# nrf5002 register map
Vendor: Nordic Semiconductor; Series: nRF50; File version: 1
CPU: CM0 r0p4, little endian, no MPU, no FPU, 2 interrupt priority bits, 32 interrupts
Registers are 32-bit, read-write, reset 0x0 unless marked. A register's access mark holds for its fields unless they carry their own. Offsets are from the block's base; [hi:lo] are bit positions; 'fields as' and 'values as' point back to an identical list.

## AAR — Accelerated Address Resolver
Base 0x4000A000; alternate view of CCM
0x00 TASKS_START wo — Start resolving addresses based on IRKs specified in the IRK data structure
  [0] TASKS_START
    1=Trigger task
0x08 TASKS_STOP wo — Stop resolving addresses
  [0] TASKS_STOP
    1=Trigger task
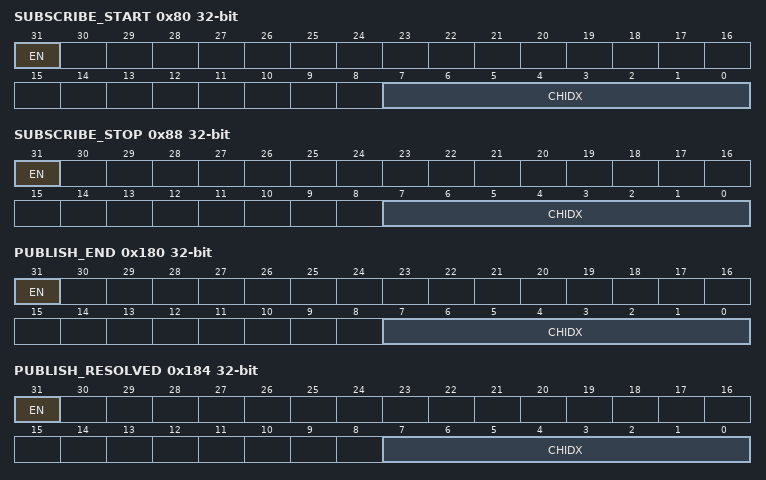
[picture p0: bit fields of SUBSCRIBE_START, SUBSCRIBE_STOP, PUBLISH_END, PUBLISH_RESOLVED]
0x80 SUBSCRIBE_START — Subscribe configuration for task START
  [31] EN
    0=Disabled (Disable subscription); 1=Enabled (Enable subscription)
  [7:0] CHIDX — DPPI channel that task START will subscribe to
0x88 SUBSCRIBE_STOP — Subscribe configuration for task STOP
  [31] EN
    values as SUBSCRIBE_START.EN
  [7:0] CHIDX — DPPI channel that task STOP will subscribe to
0x100 EVENTS_END — Address resolution procedure complete
  [0] EVENTS_END
    0=NotGenerated (Event not generated); 1=Generated (Event generated)
0x104 EVENTS_RESOLVED — Address resolved
  [0] EVENTS_RESOLVED
    values as EVENTS_END.EVENTS_END
0x108 EVENTS_NOTRESOLVED — Address not resolved
  [0] EVENTS_NOTRESOLVED
    values as EVENTS_END.EVENTS_END
0x180 PUBLISH_END — Publish configuration for event END
  [31] EN
    0=Disabled (Disable publishing); 1=Enabled (Enable publishing)
  [7:0] CHIDX — DPPI channel that event END will publish to
0x184 PUBLISH_RESOLVED — Publish configuration for event RESOLVED
  [31] EN
    values as PUBLISH_END.EN
  [7:0] CHIDX — DPPI channel that event RESOLVED will publish to
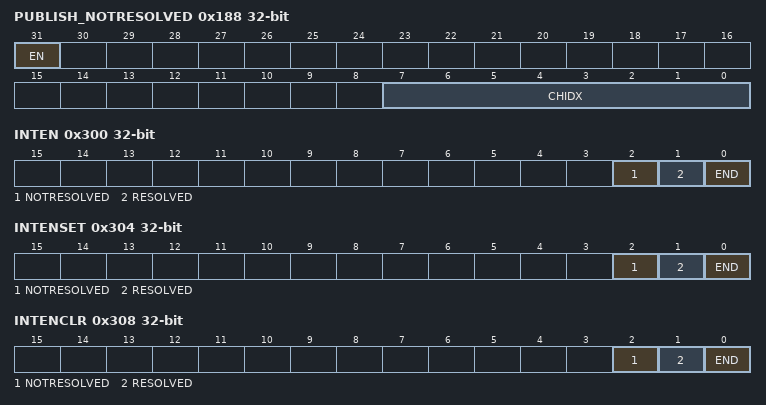
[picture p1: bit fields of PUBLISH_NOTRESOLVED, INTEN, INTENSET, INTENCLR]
0x188 PUBLISH_NOTRESOLVED — Publish configuration for event NOTRESOLVED
  [31] EN
    values as PUBLISH_END.EN
  [7:0] CHIDX — DPPI channel that event NOTRESOLVED will publish to
0x300 INTEN — Enable or disable interrupt
  [all] fields
    0=Disabled; 1=Enabled
  [2] NOTRESOLVED — Enable or disable interrupt for event NOTRESOLVED
  [1] RESOLVED — Enable or disable interrupt for event RESOLVED
  [0] END — Enable or disable interrupt for event END
0x304 INTENSET — Enable interrupt
  [all] fields
    on read: 0=Disabled (Read: Disabled); 1=Enabled (Read: Enabled) | on write: 1=Set (Enable)
  [2] NOTRESOLVED — Write '1' to enable interrupt for event NOTRESOLVED
  [1] RESOLVED — Write '1' to enable interrupt for event RESOLVED
  [0] END — Write '1' to enable interrupt for event END
0x308 INTENCLR — Disable interrupt
  [all] fields
    on read: 0=Disabled (Read: Disabled); 1=Enabled (Read: Enabled) | on write: 1=Clear (Disable)
  [2] NOTRESOLVED — Write '1' to disable interrupt for event NOTRESOLVED
  [1] RESOLVED — Write '1' to disable interrupt for event RESOLVED
  [0] END — Write '1' to disable interrupt for event END
0x400 STATUS ro — Resolution status
  [3:0] STATUS — The IRK that was used last time an address was resolved
0x500 ENABLE — Enable AAR
  [1:0] ENABLE — Enable or disable AAR
    0=Disabled; 3=Enabled
0x504 NIRK reset 0x1 — Number of IRKs
  [4:0] NIRK — Number of Identity root keys available in the IRK data structure
0x508 IRKPTR — Pointer to IRK data structure
  [31:0] IRKPTR — Pointer to the IRK data structure
0x510 ADDRPTR — Pointer to the resolvable address
  [31:0] ADDRPTR — Pointer to the resolvable address (6-bytes)
0x514 SCRATCHPTR — Pointer to data area used for temporary storage
  [31:0] SCRATCHPTR — Pointer to a scratch data area used for temporary storage during resolution. A space of minimum 3 bytes must be reserved.
0xFFC POWER reset 0x1 — Peripheral power control
  [0] POWER — Peripheral power control. The peripheral and its registers will be reset to its initial state by switching the peripheral off and then back on again. All POWER registers in AAR, CCM and ECB must be disabled to see a reset of any of those functions.
    0=Disabled (Peripheral is powered off); 1=Enabled (Peripheral is powered on)
